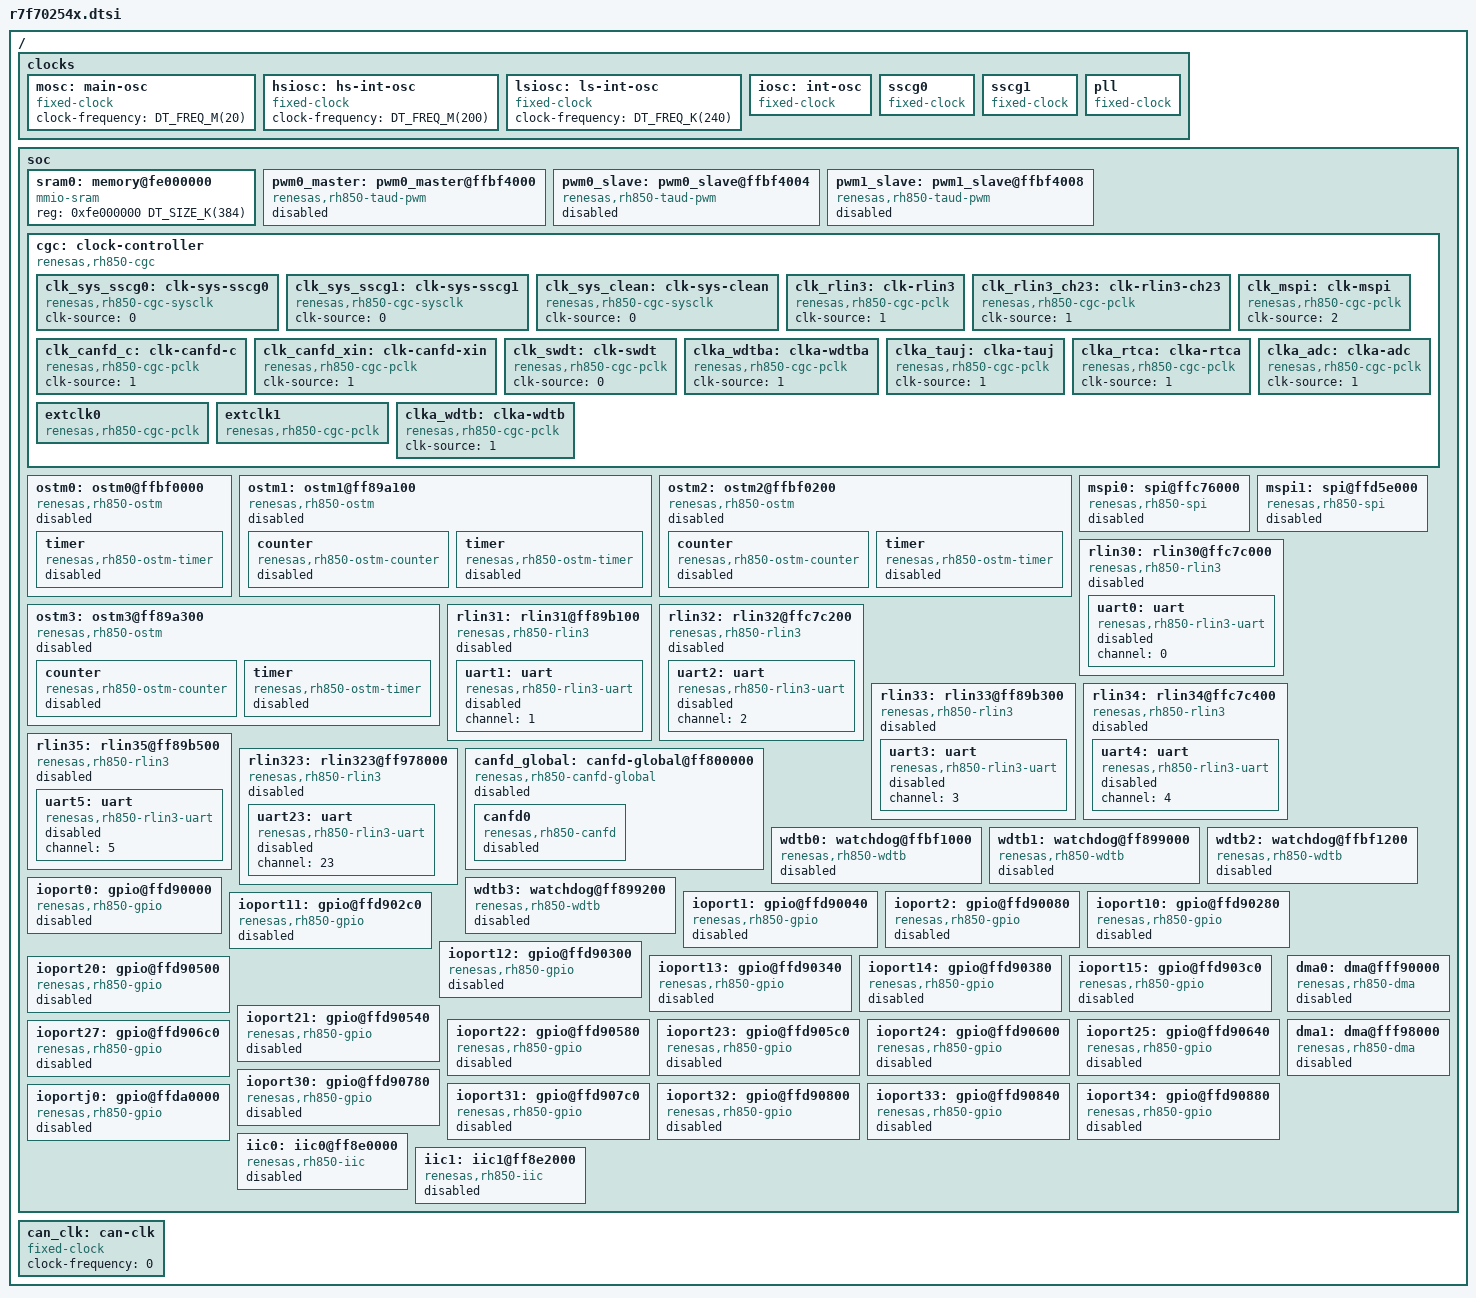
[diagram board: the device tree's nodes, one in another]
/*
 * Copyright (c) 2026 Renesas Electronics Corporation
 *
 * SPDX-License-Identifier: Apache-2.0
 */

#include <rh850/renesas/rh850u2b/u2b-g4mh-common.dtsi>
#include <zephyr/dt-bindings/clock/renesas_rh850u2b_clock.h>
#include <zephyr/dt-bindings/gpio/gpio.h>
#include <freq.h>

/ {
	clocks {
		mosc: main-osc {
			compatible = "fixed-clock";
			clock-frequency = <DT_FREQ_M(20)>;
			#clock-cells = <0>;
			status = "okay";
		};

		hsiosc: hs-int-osc {
			compatible = "fixed-clock";
			clock-frequency = <DT_FREQ_M(200)>;
			#clock-cells = <0>;
			status = "okay";
		};

		lsiosc: ls-int-osc {
			compatible = "fixed-clock";
			clock-frequency = <DT_FREQ_K(240)>;
			#clock-cells = <0>;
			status = "okay";
		};

		iosc: int-osc {
			compatible = "fixed-clock";
			clock-frequency = <DT_FREQ_M(200)>;
			clocks = <&hsiosc>;
			#clock-cells = <0>;
			status = "okay";
		};

		sscg0: sscg0 {
			compatible = "fixed-clock";
			clock-frequency = <DT_FREQ_M(800)>;
			clocks = <&mosc>;
			#clock-cells = <0>;
			status = "okay";
		};

		sscg1: sscg1 {
			compatible = "fixed-clock";
			clock-frequency = <DT_FREQ_M(800)>;
			clocks = <&mosc>;
			#clock-cells = <0>;
			status = "okay";
		};

		pll: pll {
			compatible = "fixed-clock";
			clock-frequency = <DT_FREQ_M(800)>;
			clocks = <&mosc>;
			#clock-cells = <0>;
			status = "okay";
		};
	};

	soc {
		sram0: memory@fe000000 {
			compatible = "mmio-sram";
			reg = <0xfe000000 DT_SIZE_K(384)>;
		};

		pwm0_master: pwm0_master@ffbf4000 {
			compatible = "renesas,rh850-taud-pwm";
			reg = <0xffbf4000 0x2000>;
			unit = <0>;
			channel = <0>;
			channel-type = "master";
			interrupts = <10 1>;
			interrupt-parent = <&intc2>;
			status = "disabled";
		};

		pwm0_slave: pwm0_slave@ffbf4004 {
			compatible = "renesas,rh850-taud-pwm";
			reg = <0xffbf4004 0x2000>;
			unit = <0>;
			channel = <1>;
			channel-type = "slave";
			master = <&pwm0_master>;
			interrupts = <320 1>;
			interrupt-parent = <&intc2>;
			#pwm-cells = <3>;
			status = "disabled";
		};

		pwm1_slave: pwm1_slave@ffbf4008 {
			compatible = "renesas,rh850-taud-pwm";
			reg = <0xffbf4008 0x2000>;
			unit = <0>;
			channel = <2>;
			channel-type = "slave";
			master = <&pwm0_master>;
			interrupts = <1 1>;
			interrupt-parent = <&intc2>;
			#pwm-cells = <3>;
			status = "disabled";
		};

		cgc: clock-controller {
			compatible = "renesas,rh850-cgc";
			#clock-cells = <1>;
			status = "okay";

			clk_sys_sscg0: clk-sys-sscg0 {
				compatible = "renesas,rh850-cgc-sysclk";
				clk-source = <0>;
				#clock-cells = <0>;
				status = "okay";
			};

			clk_sys_sscg1: clk-sys-sscg1 {
				compatible = "renesas,rh850-cgc-sysclk";
				clk-source = <0>;
				#clock-cells = <0>;
				status = "okay";
			};

			clk_sys_clean: clk-sys-clean {
				compatible = "renesas,rh850-cgc-sysclk";
				clk-source = <0>;
				#clock-cells = <0>;
				status = "okay";
			};

			clk_rlin3: clk-rlin3 {
				compatible = "renesas,rh850-cgc-pclk";
				clk-source = <1>;
				#clock-cells = <0>;
				status = "okay";
			};

			clk_rlin3_ch23: clk-rlin3-ch23 {
				compatible = "renesas,rh850-cgc-pclk";
				clk-source = <1>;
				#clock-cells = <0>;
				status = "okay";
			};

			clk_canfd_c: clk-canfd-c {
				compatible = "renesas,rh850-cgc-pclk";
				clk-source = <1>;
				#clock-cells = <0>;
				status = "okay";
			};

			clk_canfd_xin: clk-canfd-xin {
				compatible = "renesas,rh850-cgc-pclk";
				clk-source = <1>;
				#clock-cells = <0>;
				status = "okay";
			};

			clk_mspi: clk-mspi {
				compatible = "renesas,rh850-cgc-pclk";
				clk-source = <2>;
				#clock-cells = <0>;
				status = "okay";
			};

			clk_swdt: clk-swdt {
				compatible = "renesas,rh850-cgc-pclk";
				clk-source = <0>;
				#clock-cells = <0>;
				status = "okay";
			};

			clka_wdtba: clka-wdtba {
				compatible = "renesas,rh850-cgc-pclk";
				clk-source = <1>;
				#clock-cells = <0>;
				status = "okay";
			};

			clka_tauj: clka-tauj {
				compatible = "renesas,rh850-cgc-pclk";
				clk-source = <1>;
				#clock-cells = <0>;
				status = "okay";
			};

			clka_rtca: clka-rtca {
				compatible = "renesas,rh850-cgc-pclk";
				clk-source = <1>;
				#clock-cells = <0>;
				status = "okay";
			};

			clka_adc: clka-adc {
				compatible = "renesas,rh850-cgc-pclk";
				clk-source = <1>;
				#clock-cells = <0>;
				status = "okay";
			};

			extclk0: extclk0 {
				compatible = "renesas,rh850-cgc-pclk";
				clk-source = <4>;
				div = <0>;
				#clock-cells = <0>;
				status = "okay";
			};

			extclk1: extclk1 {
				compatible = "renesas,rh850-cgc-pclk";
				clk-source = <4>;
				div = <0>;
				#clock-cells = <0>;
				status = "okay";
			};

			clka_wdtb: clka-wdtb {
				compatible = "renesas,rh850-cgc-pclk";
				clk-source = <1>;
				#clock-cells = <0>;
				status = "okay";
			};
		};

		ostm0: ostm0@ffbf0000 {
			compatible = "renesas,rh850-ostm";
			reg = <0xffbf0000 0x20>;
			channel = <0>;
			interrupt-names = "overflow";
			interrupts = <360 1>;
			interrupt-parent = <&intc2>;
			clocks = <&cgc RH850_PCLK(OSTM, 0, PCLK)>;
			status = "disabled";

			timer {
				compatible = "renesas,rh850-ostm-timer";
				status = "disabled";
			};
		};

		ostm1: ostm1@ff89a100 {
			compatible = "renesas,rh850-ostm";
			reg = <0xff89a100 0x20>;
			channel = <1>;
			interrupt-names = "overflow";
			interrupts = <361 1>;
			interrupt-parent = <&intc2>;
			clocks = <&cgc RH850_PCLK(OSTM, 1, PCLK)>;
			status = "disabled";

			counter {
				compatible = "renesas,rh850-ostm-counter";
				status = "disabled";
			};

			timer {
				compatible = "renesas,rh850-ostm-timer";
				status = "disabled";
			};
		};

		ostm2: ostm2@ffbf0200 {
			compatible = "renesas,rh850-ostm";
			reg = <0xffbf0200 0x20>;
			channel = <2>;
			interrupt-names = "overflow";
			interrupts = <841 1>;
			interrupt-parent = <&intc2>;
			clocks = <&cgc RH850_PCLK(OSTM, 2, PCLK)>;
			status = "disabled";

			counter {
				compatible = "renesas,rh850-ostm-counter";
				status = "disabled";
			};

			timer {
				compatible = "renesas,rh850-ostm-timer";
				status = "disabled";
			};
		};

		ostm3: ostm3@ff89a300 {
			compatible = "renesas,rh850-ostm";
			reg = <0xff89a300 0x20>;
			channel = <3>;
			interrupt-names = "overflow";
			interrupts = <842 1>;
			interrupt-parent = <&intc2>;
			clocks = <&cgc RH850_PCLK(OSTM, 3, PCLK)>;
			status = "disabled";

			counter {
				compatible = "renesas,rh850-ostm-counter";
				status = "disabled";
			};

			timer {
				compatible = "renesas,rh850-ostm-timer";
				status = "disabled";
			};
		};

		mspi0: spi@ffc76000 {
			compatible = "renesas,rh850-spi";
			interrupts = <576 1>, <577 1>, <578 1>, <579 1>;
			interrupt-names = "txi", "rxi", "tei", "eri";
			reg = <0xffc76000 0x680>;
			interrupt-parent = <&intc2>;
			#address-cells = <1>;
			#size-cells = <0>;
			channel = <0>;
			status = "disabled";
		};

		mspi1: spi@ffd5e000 {
			compatible = "renesas,rh850-spi";
			interrupts = <580 1>, <581 1>, <582 1>, <583 1>;
			interrupt-names = "txi", "rxi", "tei", "eri";
			reg = <0xffd5e000 0x680>;
			interrupt-parent = <&intc2>;
			#address-cells = <1>;
			#size-cells = <0>;
			channel = <0>;
			status = "disabled";
		};

		rlin30: rlin30@ffc7c000 {
			compatible = "renesas,rh850-rlin3";
			interrupts = <620 1>, <621 1>, <622 1>, <623 1>;
			interrupt-names = "rlin3i", "txi", "rxi", "eri";
			reg = <0xffc7c000 0x35>;
			interrupt-parent = <&intc2>;
			clocks = <&cgc RH850_PCLK(RLIN3, 0, RLIN3)>;
			status = "disabled";

			uart0: uart {
				compatible = "renesas,rh850-rlin3-uart";
				channel = <0>;
				status = "disabled";
			};
		};

		rlin31: rlin31@ff89b100 {
			compatible = "renesas,rh850-rlin3";
			interrupts = <625 1>, <626 1>, <627 1>, <628 1>;
			interrupt-names = "rlin3i", "txi", "rxi", "eri";
			reg = <0xff89b100 0x35>;
			interrupt-parent = <&intc2>;
			clocks = <&cgc RH850_PCLK(RLIN3, 1, RLIN3)>;
			status = "disabled";

			uart1: uart {
				compatible = "renesas,rh850-rlin3-uart";
				channel = <1>;
				status = "disabled";
			};
		};

		rlin32: rlin32@ffc7c200 {
			compatible = "renesas,rh850-rlin3";
			interrupts = <630 1>, <631 1>, <632 1>, <633 1>;
			interrupt-names = "rlin3i", "txi", "rxi", "eri";
			reg = <0xffc7c200 0x35>;
			interrupt-parent = <&intc2>;
			clocks = <&cgc RH850_PCLK(RLIN3, 2, RLIN3)>;
			status = "disabled";

			uart2: uart {
				compatible = "renesas,rh850-rlin3-uart";
				channel = <2>;
				status = "disabled";
			};
		};

		rlin33: rlin33@ff89b300 {
			compatible = "renesas,rh850-rlin3";
			interrupts = <635 1>, <636 1>, <637 1>, <638 1>;
			interrupt-names = "rlin3i", "txi", "rxi", "eri";
			reg = <0xff89b300 0x35>;
			interrupt-parent = <&intc2>;
			clocks = <&cgc RH850_PCLK(RLIN3, 3, RLIN3)>;
			status = "disabled";

			uart3: uart {
				compatible = "renesas,rh850-rlin3-uart";
				channel = <3>;
				status = "disabled";
			};
		};

		rlin34: rlin34@ffc7c400 {
			compatible = "renesas,rh850-rlin3";
			interrupts = <640 1>, <641 1>, <642 1>, <643 1>;
			interrupt-names = "rlin3i", "txi", "rxi", "eri";
			reg = <0xffc7c400 0x35>;
			interrupt-parent = <&intc2>;
			clocks = <&cgc RH850_PCLK(RLIN3, 4, RLIN3)>;
			status = "disabled";

			uart4: uart {
				compatible = "renesas,rh850-rlin3-uart";
				channel = <4>;
				status = "disabled";
			};
		};

		rlin35: rlin35@ff89b500 {
			compatible = "renesas,rh850-rlin3";
			interrupts = <644 1>, <645 1>, <646 1>, <647 1>;
			interrupt-names = "rlin3i", "txi", "rxi", "eri";
			reg = <0xff89b500 0x35>;
			interrupt-parent = <&intc2>;
			clocks = <&cgc RH850_PCLK(RLIN3, 5, RLIN3)>;
			status = "disabled";

			uart5: uart {
				compatible = "renesas,rh850-rlin3-uart";
				channel = <5>;
				status = "disabled";
			};
		};

		rlin323: rlin323@ff978000 {
			compatible = "renesas,rh850-rlin3";
			interrupts = <648 1>, <649 1>, <650 1>, <651 1>;
			interrupt-names = "rlin3i", "txi", "rxi", "eri";
			reg = <0xff978000 0x35>;
			interrupt-parent = <&intc2>;
			clocks = <&cgc RH850_PCLK(RLIN3, 23, CH23_RLIN3)>;
			status = "disabled";

			uart23: uart {
				compatible = "renesas,rh850-rlin3-uart";
				channel = <23>;
				status = "disabled";
			};
		};

		canfd_global: canfd-global@ff800000 {
			compatible = "renesas,rh850-canfd-global";
			reg = <0xff800000 DT_SIZE_K(128)>;
			interrupts = <652 1>, <653 1>;
			interrupt-names = "g_err", "g_recc";
			interrupt-parent = <&intc2>;
			status = "disabled";

			canfd0: canfd0 {
				compatible = "renesas,rh850-canfd";
				channel = <0>;
				interrupts = <659 1>, <658 1>, <660 1>;
				interrupt-names = "rxi", "eri", "txi";
				interrupt-parent = <&intc2>;
				clock-frequency = <80000000>;
				status = "disabled";
			};
		};

		wdtb0: watchdog@ffbf1000 {
			unit = <1>;
			compatible = "renesas,rh850-wdtb";
			interrupts = <22 0>;
			window-open-mode = "select-by-window-start";
			error-mode = "nmi-mode";
			clock-freq = <312500>;
			reg = <0xffbf1000 0x14>;
			interrupt-parent = <&intc2>;
			status = "disabled";
		};

		wdtb1: watchdog@ff899000 {
			unit = <2>;
			compatible = "renesas,rh850-wdtb";
			interrupts = <22 0>;
			window-open-mode = "select-by-window-start";
			error-mode = "nmi-mode";
			clock-freq = <312500>;
			reg = <0xff899000 0x14>;
			interrupt-parent = <&intc2>;
			status = "disabled";
		};

		wdtb2: watchdog@ffbf1200 {
			unit = <3>;
			compatible = "renesas,rh850-wdtb";
			interrupts = <22 0>;
			window-open-mode = "select-by-window-start";
			error-mode = "nmi-mode";
			clock-freq = <312500>;
			reg = <0xffbf1200 0x14>;
			interrupt-parent = <&intc2>;
			status = "disabled";
		};

		wdtb3: watchdog@ff899200 {
			unit = <4>;
			compatible = "renesas,rh850-wdtb";
			interrupts = <22 0>;
			window-open-mode = "select-by-window-start";
			error-mode = "nmi-mode";
			clock-freq = <312500>;
			reg = <0xff899200 0x14>;
			interrupt-parent = <&intc2>;
			status = "disabled";
		};

		ioport0: gpio@ffd90000 {
			compatible = "renesas,rh850-gpio";
			reg = <0xffd90000 0x40>;
			port = <0>;
			protected-write-mask = <0>;
			port-type = "port";
			#gpio-cells = <2>;
			gpio-controller;
			status = "disabled";
		};

		ioport1: gpio@ffd90040 {
			compatible = "renesas,rh850-gpio";
			reg = <0xffd90040 0x40>;
			port = <1>;
			protected-write-mask = <1>;
			port-type = "port";
			#gpio-cells = <2>;
			gpio-controller;
			status = "disabled";
		};

		ioport2: gpio@ffd90080 {
			compatible = "renesas,rh850-gpio";
			reg = <0xffd90080 0x40>;
			port = <2>;
			protected-write-mask = <2>;
			port-type = "port";
			#gpio-cells = <2>;
			gpio-controller;
			status = "disabled";
		};

		ioport10: gpio@ffd90280 {
			compatible = "renesas,rh850-gpio";
			reg = <0xffd90280 0x40>;
			port = <10>;
			protected-write-mask = <3>;
			port-type = "port";
			#gpio-cells = <2>;
			gpio-controller;
			status = "disabled";
		};

		ioport11: gpio@ffd902c0 {
			compatible = "renesas,rh850-gpio";
			reg = <0xffd902c0 0x40>;
			port = <11>;
			protected-write-mask = <4>;
			port-type = "port";
			#gpio-cells = <2>;
			gpio-controller;
			status = "disabled";
		};

		ioport12: gpio@ffd90300 {
			compatible = "renesas,rh850-gpio";
			reg = <0xffd90300 0x40>;
			port = <12>;
			protected-write-mask = <5>;
			port-type = "port";
			#gpio-cells = <2>;
			gpio-controller;
			status = "disabled";
		};

		ioport13: gpio@ffd90340 {
			compatible = "renesas,rh850-gpio";
			reg = <0xffd90340 0x40>;
			port = <13>;
			protected-write-mask = <6>;
			port-type = "port";
			#gpio-cells = <2>;
			gpio-controller;
			status = "disabled";
		};

		ioport14: gpio@ffd90380 {
			compatible = "renesas,rh850-gpio";
			reg = <0xffd90380 0x40>;
			port = <14>;
			protected-write-mask = <7>;
			port-type = "port";
			#gpio-cells = <2>;
			gpio-controller;
			status = "disabled";
		};

		ioport15: gpio@ffd903c0 {
			compatible = "renesas,rh850-gpio";
			reg = <0xffd903c0 0x40>;
			port = <15>;
			protected-write-mask = <8>;
			port-type = "port";
			#gpio-cells = <2>;
			gpio-controller;
			status = "disabled";
		};

		ioport20: gpio@ffd90500 {
			compatible = "renesas,rh850-gpio";
			reg = <0xffd90500 0x40>;
			port = <20>;
			protected-write-mask = <9>;
			port-type = "port";
			#gpio-cells = <2>;
			gpio-controller;
			status = "disabled";
		};

		ioport21: gpio@ffd90540 {
			compatible = "renesas,rh850-gpio";
			reg = <0xffd90540 0x40>;
			port = <21>;
			protected-write-mask = <10>;
			port-type = "port";
			#gpio-cells = <2>;
			gpio-controller;
			status = "disabled";
		};

		ioport22: gpio@ffd90580 {
			compatible = "renesas,rh850-gpio";
			reg = <0xffd90580 0x40>;
			port = <22>;
			protected-write-mask = <11>;
			port-type = "port";
			#gpio-cells = <2>;
			gpio-controller;
			status = "disabled";
		};

		ioport23: gpio@ffd905c0 {
			compatible = "renesas,rh850-gpio";
			reg = <0xffd905c0 0x40>;
			port = <23>;
			protected-write-mask = <12>;
			port-type = "port";
			#gpio-cells = <2>;
			gpio-controller;
			status = "disabled";
		};

		ioport24: gpio@ffd90600 {
			compatible = "renesas,rh850-gpio";
			reg = <0xffd90600 0x40>;
			port = <24>;
			protected-write-mask = <13>;
			port-type = "port";
			#gpio-cells = <2>;
			gpio-controller;
			status = "disabled";
		};

		ioport25: gpio@ffd90640 {
			compatible = "renesas,rh850-gpio";
			reg = <0xffd90640 0x40>;
			port = <25>;
			protected-write-mask = <14>;
			port-type = "port";
			#gpio-cells = <2>;
			gpio-controller;
			status = "disabled";
		};

		ioport27: gpio@ffd906c0 {
			compatible = "renesas,rh850-gpio";
			reg = <0xffd906c0 0x40>;
			port = <27>;
			protected-write-mask = <16>;
			port-type = "port";
			#gpio-cells = <2>;
			gpio-controller;
			status = "disabled";
		};

		ioport30: gpio@ffd90780 {
			compatible = "renesas,rh850-gpio";
			reg = <0xffd90780 0x40>;
			port = <30>;
			protected-write-mask = <17>;
			port-type = "port";
			#gpio-cells = <2>;
			gpio-controller;
			status = "disabled";
		};

		ioport31: gpio@ffd907c0 {
			compatible = "renesas,rh850-gpio";
			reg = <0xffd907c0 0x40>;
			port = <31>;
			protected-write-mask = <18>;
			port-type = "port";
			#gpio-cells = <2>;
			gpio-controller;
			status = "disabled";
		};

		ioport32: gpio@ffd90800 {
			compatible = "renesas,rh850-gpio";
			reg = <0xffd90800 0x40>;
			port = <32>;
			protected-write-mask = <19>;
			port-type = "port";
			#gpio-cells = <2>;
			gpio-controller;
			status = "disabled";
		};

		ioport33: gpio@ffd90840 {
			compatible = "renesas,rh850-gpio";
			reg = <0xffd90840 0x40>;
			port = <33>;
			protected-write-mask = <20>;
			port-type = "port";
			#gpio-cells = <2>;
			gpio-controller;
			status = "disabled";
		};

		ioport34: gpio@ffd90880 {
			compatible = "renesas,rh850-gpio";
			reg = <0xffd90880 0x40>;
			port = <34>;
			protected-write-mask = <21>;
			port-type = "port";
			#gpio-cells = <2>;
			gpio-controller;
			status = "disabled";
		};

		ioportj0: gpio@ffda0000 {
			compatible = "renesas,rh850-gpio";
			reg = <0xffda0000 0x40>;
			port = <0>;
			protected-write-mask = <255>;
			port-type = "jport";
			#gpio-cells = <2>;
			gpio-controller;
			status = "disabled";
		};

		iic0: iic0@ff8e0000 {
			compatible = "renesas,rh850-iic";
			interrupts = <882 1>, <883 1>, <886 1>, <887 1>;
			interrupt-names = "rxi", "txi", "eri", "tei";
			reg = <0xff8e0000 0x2000>;
			interrupt-parent = <&intc2>;
			#address-cells = <1>;
			#size-cells = <0>;
			channel = <0>;
			status = "disabled";
		};

		iic1: iic1@ff8e2000 {
			compatible = "renesas,rh850-iic";
			interrupts = <884 1>, <885 1>, <888 1>, <889 1>;
			interrupt-names = "rxi", "txi", "eri", "tei";
			reg = <0xff8e2000 0x2000>;
			interrupt-parent = <&intc2>;
			#address-cells = <1>;
			#size-cells = <0>;
			channel = <1>;
			status = "disabled";
		};

		dma0: dma@fff90000 {
			compatible = "renesas,rh850-dma";
			reg = <0xfff90000 0x5000>, <0xfff95000 0x020>;
			reg-names = "reg_main", "ext";
			interrupts = <70 1>, <71 1>, <72 1>, <73 1>,
				     <74 1>, <75 1>, <76 1>, <77 1>,
				     <78 1>, <79 1>, <80 1>, <81 1>,
				     <82 1>, <83 1>, <84 1>, <85 1>;
			interrupt-names = "ch0", "ch1", "ch2", "ch3",
					  "ch4", "ch5", "ch6", "ch7",
					  "ch8", "ch9", "ch10", "ch11",
					  "ch12", "ch13", "ch14", "ch15";
			interrupt-parent = <&intc2>;
			dma-unit = <0>;
			dma-channels = <16>;
			#dma-cells = <2>;
			status = "disabled";
		};

		dma1: dma@fff98000 {
			compatible = "renesas,rh850-dma";
			reg = <0xfff98000 0x5000>, <0xfff9d000 0x020>;
			reg-names = "reg_main", "ext";
			interrupts = <825 1>, <826 1>, <827 1>, <828 1>,
				     <829 1>, <830 1>, <831 1>, <832 1>,
				     <833 1>, <834 1>, <835 1>, <836 1>,
				     <837 1>, <838 1>, <839 1>, <840 1>;
			interrupt-names = "ch0", "ch1", "ch2", "ch3",
					  "ch4", "ch5", "ch6", "ch7",
					  "ch8", "ch9", "ch10", "ch11",
					  "ch12", "ch13", "ch14", "ch15";
			interrupt-parent = <&intc2>;
			dma-unit = <1>;
			dma-channels = <16>;
			#dma-cells = <2>;
			status = "disabled";
		};
	};

	/* External CAN clock - to be overridden by boards that provide it */
	can_clk: can-clk {
		compatible = "fixed-clock";
		clock-frequency = <0>;
		#clock-cells = <0>;
	};
};
